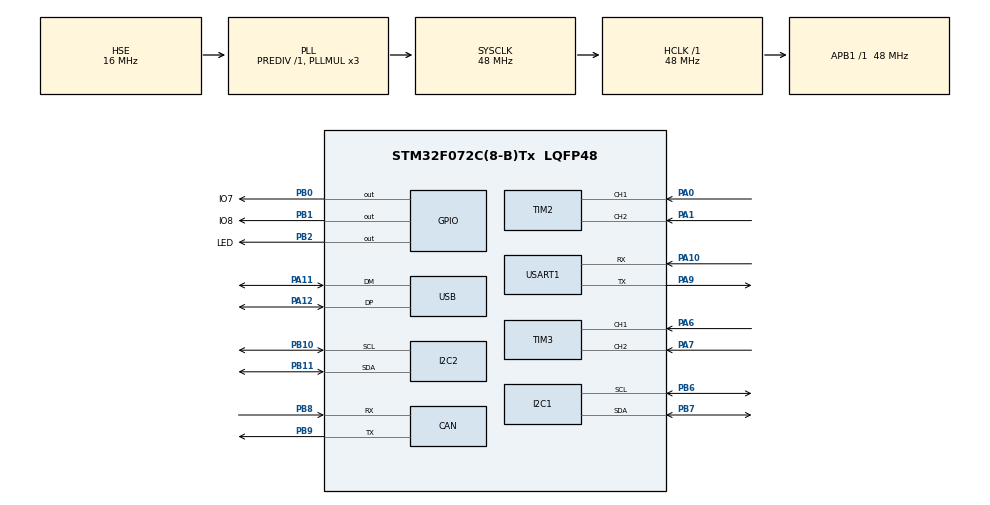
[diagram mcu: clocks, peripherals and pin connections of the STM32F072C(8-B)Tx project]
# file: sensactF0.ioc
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CAN.CalculateTimeQuantum=333.3333333333333
Mcu.Family=STM32F0
Mcu.Name=STM32F072C(8-B)Tx
Mcu.Package=LQFP48
PA0.Signal=S_TIM2_CH1_ETR
PA1.Signal=S_TIM2_CH2
PA10.Mode=Asynchronous
PA10.Signal=USART1_RX
PA11.Mode=Device
PA11.Signal=USB_DM
PA12.Mode=Device
PA12.Signal=USB_DP
PA13.Mode=Serial_Wire
PA13.Signal=SYS_SWDIO
PA14.Mode=Serial_Wire
PA14.Signal=SYS_SWCLK
PA6.Signal=S_TIM3_CH1
PA7.Signal=S_TIM3_CH2
PA9.Mode=Asynchronous
PA9.Signal=USART1_TX
PB0.GPIO_Label=IO7
PB0.Signal=GPIO_Output
PB1.GPIO_Label=IO8
PB1.Signal=GPIO_Output
PB10.Mode=I2C
PB10.Signal=I2C2_SCL
PB11.Mode=I2C
PB11.Signal=I2C2_SDA
PB2.GPIO_Label=LED
PB2.Signal=GPIO_Output
PB6.Mode=I2C
PB6.Signal=I2C1_SCL
PB7.Mode=I2C
PB7.Signal=I2C1_SDA
PB8.Mode=Master
PB8.Signal=CAN_RX
PB9.Mode=Master
PB9.Signal=CAN_TX
PF0-OSC_IN.Mode=HSE-External-Oscillator
PF0-OSC_IN.Signal=RCC_OSC_IN
PF1-OSC_OUT.Mode=HSE-External-Oscillator
PF1-OSC_OUT.Signal=RCC_OSC_OUT
ProjectManager.HeapSize=0x200
ProjectManager.StackSize=0x400
ProjectManager.TargetToolchain=TrueSTUDIO
RCC.AHBFreq_Value=48000000
RCC.APB1Freq_Value=48000000
RCC.APB1TimFreq_Value=48000000
RCC.HCLKFreq_Value=48000000
RCC.HSE_VALUE=16000000
RCC.PLLMUL=RCC_PLL_MUL3
RCC.PLLSourceVirtual=RCC_PLLSOURCE_HSE
RCC.SYSCLKFreq_VALUE=48000000
RCC.SYSCLKSource=RCC_SYSCLKSOURCE_PLLCLK
SH.S_TIM2_CH1_ETR.0=TIM2_CH1,Input_Capture1_from_TI1
SH.S_TIM2_CH2.0=TIM2_CH2,Input_Capture2_from_TI2
SH.S_TIM3_CH1.0=TIM3_CH1,Input_Capture1_from_TI1
SH.S_TIM3_CH2.0=TIM3_CH2,Input_Capture2_from_TI2
TIM2.Channel-Input_Capture1_from_TI1=TIM_CHANNEL_1
TIM2.Channel-Input_Capture2_from_TI2=TIM_CHANNEL_2
TIM3.Channel-Input_Capture1_from_TI1=TIM_CHANNEL_1
TIM3.Channel-Input_Capture2_from_TI2=TIM_CHANNEL_2
USART1.VirtualMode-Asynchronous=VM_ASYNC
VP_TIM2_VS_ClockSourceINT.Mode=Internal
board=sensactF0

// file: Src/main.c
/**
  ******************************************************************************
  * @file           : main.c
  * @brief          : Main program body
  ******************************************************************************
  ** This notice applies to any and all portions of this file
  * that are not between comment pairs USER CODE BEGIN and
  * USER CODE END. Other portions of this file, whether
  * inserted by the user or by software development tools
  * are owned by their respective copyright owners.
  *
  * COPYRIGHT(c) 2018 STMicroelectronics
  *
  * Redistribution and use in source and binary forms, with or without modification,
  * are permitted provided that the following conditions are met:
  *   1. Redistributions of source code must retain the above copyright notice,
  *      this list of conditions and the following disclaimer.
  *   2. Redistributions in binary form must reproduce the above copyright notice,
  *      this list of conditions and the following disclaimer in the documentation
  *      and/or other materials provided with the distribution.
  *   3. Neither the name of STMicroelectronics nor the names of its contributors
  *      may be used to endorse or promote products derived from this software
  *      without specific prior written permission.
  *
  * THIS SOFTWARE IS PROVIDED BY THE COPYRIGHT HOLDERS AND CONTRIBUTORS "AS IS"
  * AND ANY EXPRESS OR IMPLIED WARRANTIES, INCLUDING, BUT NOT LIMITED TO, THE
  * IMPLIED WARRANTIES OF MERCHANTABILITY AND FITNESS FOR A PARTICULAR PURPOSE ARE
  * DISCLAIMED. IN NO EVENT SHALL THE COPYRIGHT HOLDER OR CONTRIBUTORS BE LIABLE
  * FOR ANY DIRECT, INDIRECT, INCIDENTAL, SPECIAL, EXEMPLARY, OR CONSEQUENTIAL
  * DAMAGES (INCLUDING, BUT NOT LIMITED TO, PROCUREMENT OF SUBSTITUTE GOODS OR
  * SERVICES; LOSS OF USE, DATA, OR PROFITS; OR BUSINESS INTERRUPTION) HOWEVER
  * CAUSED AND ON ANY THEORY OF LIABILITY, WHETHER IN CONTRACT, STRICT LIABILITY,
  * OR TORT (INCLUDING NEGLIGENCE OR OTHERWISE) ARISING IN ANY WAY OUT OF THE USE
  * OF THIS SOFTWARE, EVEN IF ADVISED OF THE POSSIBILITY OF SUCH DAMAGE.
  *
  ******************************************************************************
  */
#include "main.h"
#include "stm32f0xx_hal.h"

CAN_HandleTypeDef hcan;

I2C_HandleTypeDef hi2c1;
I2C_HandleTypeDef hi2c2;

TIM_HandleTypeDef htim2;
TIM_HandleTypeDef htim3;

UART_HandleTypeDef huart1;

PCD_HandleTypeDef hpcd_USB_FS;

/* USER CODE BEGIN PV */
/* Private variables ---------------------------------------------------------*/

/* USER CODE END PV */

void SystemClock_Config(void);
static void MX_GPIO_Init(void);
static void MX_USB_PCD_Init(void);
static void MX_USART1_UART_Init(void);
static void MX_I2C1_Init(void);
static void MX_I2C2_Init(void);
static void MX_CAN_Init(void);
static void MX_TIM2_Init(void);
static void MX_TIM3_Init(void);

/* USER CODE BEGIN PFP */
/* Private function prototypes -----------------------------------------------*/

/* USER CODE END PFP */

int main(void)
{

  /* MCU Configuration----------------------------------------------------------*/

  /* Reset of all peripherals, Initializes the Flash interface and the Systick. */
  HAL_Init();

  /* Configure the system clock */
  SystemClock_Config();

  /* Initialize all configured peripherals */
  MX_GPIO_Init();
  MX_USB_PCD_Init();
  MX_USART1_UART_Init();
  MX_I2C1_Init();
  MX_I2C2_Init();
  MX_CAN_Init();
  MX_TIM2_Init();
  MX_TIM3_Init();

  /* Infinite loop */
  /* USER CODE BEGIN WHILE */
  while (1)
  {
	  HAL_Delay(200);
	  HAL_GPIO_TogglePin(GPIOB, GPIO_PIN_1);
  /* USER CODE END WHILE */

  }

}

void SystemClock_Config(void)
{

  RCC_OscInitTypeDef RCC_OscInitStruct;
  RCC_ClkInitTypeDef RCC_ClkInitStruct;
  RCC_PeriphCLKInitTypeDef PeriphClkInit;

    /**Initializes the CPU, AHB and APB busses clocks
    */
  RCC_OscInitStruct.OscillatorType = RCC_OSCILLATORTYPE_HSI|RCC_OSCILLATORTYPE_HSI48
                              |RCC_OSCILLATORTYPE_HSE;
  RCC_OscInitStruct.HSEState = RCC_HSE_ON;
  RCC_OscInitStruct.HSIState = RCC_HSI_ON;
  RCC_OscInitStruct.HSI48State = RCC_HSI48_ON;
  RCC_OscInitStruct.HSICalibrationValue = 16;
  RCC_OscInitStruct.PLL.PLLState = RCC_PLL_ON;
  RCC_OscInitStruct.PLL.PLLSource = RCC_PLLSOURCE_HSE;
  RCC_OscInitStruct.PLL.PLLMUL = RCC_PLL_MUL3;
  RCC_OscInitStruct.PLL.PREDIV = RCC_PREDIV_DIV1;
  if (HAL_RCC_OscConfig(&RCC_OscInitStruct) != HAL_OK)
  {
    _Error_Handler(__FILE__, __LINE__);
  }

    /**Initializes the CPU, AHB and APB busses clocks
    */
  RCC_ClkInitStruct.ClockType = RCC_CLOCKTYPE_HCLK|RCC_CLOCKTYPE_SYSCLK
                              |RCC_CLOCKTYPE_PCLK1;
  RCC_ClkInitStruct.SYSCLKSource = RCC_SYSCLKSOURCE_PLLCLK;
  RCC_ClkInitStruct.AHBCLKDivider = RCC_SYSCLK_DIV1;
  RCC_ClkInitStruct.APB1CLKDivider = RCC_HCLK_DIV1;

  if (HAL_RCC_ClockConfig(&RCC_ClkInitStruct, FLASH_LATENCY_1) != HAL_OK)
  {
    _Error_Handler(__FILE__, __LINE__);
  }

  PeriphClkInit.PeriphClockSelection = RCC_PERIPHCLK_USB|RCC_PERIPHCLK_USART1
                              |RCC_PERIPHCLK_I2C1;
  PeriphClkInit.Usart1ClockSelection = RCC_USART1CLKSOURCE_PCLK1;
  PeriphClkInit.I2c1ClockSelection = RCC_I2C1CLKSOURCE_HSI;
  PeriphClkInit.UsbClockSelection = RCC_USBCLKSOURCE_HSI48;

  if (HAL_RCCEx_PeriphCLKConfig(&PeriphClkInit) != HAL_OK)
  {
    _Error_Handler(__FILE__, __LINE__);
  }

    /**Configure the Systick interrupt time
    */
  HAL_SYSTICK_Config(HAL_RCC_GetHCLKFreq()/1000);

    /**Configure the Systick
    */
  HAL_SYSTICK_CLKSourceConfig(SYSTICK_CLKSOURCE_HCLK);

  /* SysTick_IRQn interrupt configuration */
  HAL_NVIC_SetPriority(SysTick_IRQn, 0, 0);
}

/* CAN init function */
static void MX_CAN_Init(void)
{

  hcan.Instance = CAN;
  hcan.Init.Prescaler = 16;
  hcan.Init.Mode = CAN_MODE_NORMAL;
  hcan.Init.SJW = CAN_SJW_1TQ;
  hcan.Init.BS1 = CAN_BS1_1TQ;
  hcan.Init.BS2 = CAN_BS2_1TQ;
  hcan.Init.TTCM = DISABLE;
  hcan.Init.ABOM = DISABLE;
  hcan.Init.AWUM = DISABLE;
  hcan.Init.NART = DISABLE;
  hcan.Init.RFLM = DISABLE;
  hcan.Init.TXFP = DISABLE;
  if (HAL_CAN_Init(&hcan) != HAL_OK)
  {
    _Error_Handler(__FILE__, __LINE__);
  }

}

/* I2C1 init function */
static void MX_I2C1_Init(void)
{

  hi2c1.Instance = I2C1;
  hi2c1.Init.Timing = 0x2000090E;
  hi2c1.Init.OwnAddress1 = 0;
  hi2c1.Init.AddressingMode = I2C_ADDRESSINGMODE_7BIT;
  hi2c1.Init.DualAddressMode = I2C_DUALADDRESS_DISABLE;
  hi2c1.Init.OwnAddress2 = 0;
  hi2c1.Init.OwnAddress2Masks = I2C_OA2_NOMASK;
  hi2c1.Init.GeneralCallMode = I2C_GENERALCALL_DISABLE;
  hi2c1.Init.NoStretchMode = I2C_NOSTRETCH_DISABLE;
  if (HAL_I2C_Init(&hi2c1) != HAL_OK)
  {
    _Error_Handler(__FILE__, __LINE__);
  }

    /**Configure Analogue filter
    */
  if (HAL_I2CEx_ConfigAnalogFilter(&hi2c1, I2C_ANALOGFILTER_ENABLE) != HAL_OK)
  {
    _Error_Handler(__FILE__, __LINE__);
  }

    /**Configure Digital filter
    */
  if (HAL_I2CEx_ConfigDigitalFilter(&hi2c1, 0) != HAL_OK)
  {
    _Error_Handler(__FILE__, __LINE__);
  }

}

/* I2C2 init function */
static void MX_I2C2_Init(void)
{

  hi2c2.Instance = I2C2;
  hi2c2.Init.Timing = 0x2000090E;
  hi2c2.Init.OwnAddress1 = 0;
  hi2c2.Init.AddressingMode = I2C_ADDRESSINGMODE_7BIT;
  hi2c2.Init.DualAddressMode = I2C_DUALADDRESS_DISABLE;
  hi2c2.Init.OwnAddress2 = 0;
  hi2c2.Init.OwnAddress2Masks = I2C_OA2_NOMASK;
  hi2c2.Init.GeneralCallMode = I2C_GENERALCALL_DISABLE;
  hi2c2.Init.NoStretchMode = I2C_NOSTRETCH_DISABLE;
  if (HAL_I2C_Init(&hi2c2) != HAL_OK)
  {
    _Error_Handler(__FILE__, __LINE__);
  }

    /**Configure Analogue filter
    */
  if (HAL_I2CEx_ConfigAnalogFilter(&hi2c2, I2C_ANALOGFILTER_ENABLE) != HAL_OK)
  {
    _Error_Handler(__FILE__, __LINE__);
  }

    /**Configure Digital filter
    */
  if (HAL_I2CEx_ConfigDigitalFilter(&hi2c2, 0) != HAL_OK)
  {
    _Error_Handler(__FILE__, __LINE__);
  }

}

/* TIM2 init function */
static void MX_TIM2_Init(void)
{

  TIM_ClockConfigTypeDef sClockSourceConfig;
  TIM_MasterConfigTypeDef sMasterConfig;
  TIM_IC_InitTypeDef sConfigIC;

  htim2.Instance = TIM2;
  htim2.Init.Prescaler = 0;
  htim2.Init.CounterMode = TIM_COUNTERMODE_UP;
  htim2.Init.Period = 0;
  htim2.Init.ClockDivision = TIM_CLOCKDIVISION_DIV1;
  htim2.Init.AutoReloadPreload = TIM_AUTORELOAD_PRELOAD_DISABLE;
  if (HAL_TIM_Base_Init(&htim2) != HAL_OK)
  {
    _Error_Handler(__FILE__, __LINE__);
  }

  sClockSourceConfig.ClockSource = TIM_CLOCKSOURCE_INTERNAL;
  if (HAL_TIM_ConfigClockSource(&htim2, &sClockSourceConfig) != HAL_OK)
  {
    _Error_Handler(__FILE__, __LINE__);
  }

  if (HAL_TIM_IC_Init(&htim2) != HAL_OK)
  {
    _Error_Handler(__FILE__, __LINE__);
  }

  sMasterConfig.MasterOutputTrigger = TIM_TRGO_RESET;
  sMasterConfig.MasterSlaveMode = TIM_MASTERSLAVEMODE_DISABLE;
  if (HAL_TIMEx_MasterConfigSynchronization(&htim2, &sMasterConfig) != HAL_OK)
  {
    _Error_Handler(__FILE__, __LINE__);
  }

  sConfigIC.ICPolarity = TIM_INPUTCHANNELPOLARITY_RISING;
  sConfigIC.ICSelection = TIM_ICSELECTION_DIRECTTI;
  sConfigIC.ICPrescaler = TIM_ICPSC_DIV1;
  sConfigIC.ICFilter = 0;
  if (HAL_TIM_IC_ConfigChannel(&htim2, &sConfigIC, TIM_CHANNEL_1) != HAL_OK)
  {
    _Error_Handler(__FILE__, __LINE__);
  }

  if (HAL_TIM_IC_ConfigChannel(&htim2, &sConfigIC, TIM_CHANNEL_2) != HAL_OK)
  {
    _Error_Handler(__FILE__, __LINE__);
  }

}

/* TIM3 init function */
static void MX_TIM3_Init(void)
{

  TIM_MasterConfigTypeDef sMasterConfig;
  TIM_IC_InitTypeDef sConfigIC;

  htim3.Instance = TIM3;
  htim3.Init.Prescaler = 0;
  htim3.Init.CounterMode = TIM_COUNTERMODE_UP;
  htim3.Init.Period = 0;
  htim3.Init.ClockDivision = TIM_CLOCKDIVISION_DIV1;
  htim3.Init.AutoReloadPreload = TIM_AUTORELOAD_PRELOAD_DISABLE;
  if (HAL_TIM_IC_Init(&htim3) != HAL_OK)
  {
    _Error_Handler(__FILE__, __LINE__);
  }

  sMasterConfig.MasterOutputTrigger = TIM_TRGO_RESET;
  sMasterConfig.MasterSlaveMode = TIM_MASTERSLAVEMODE_DISABLE;
  if (HAL_TIMEx_MasterConfigSynchronization(&htim3, &sMasterConfig) != HAL_OK)
  {
    _Error_Handler(__FILE__, __LINE__);
  }

  sConfigIC.ICPolarity = TIM_INPUTCHANNELPOLARITY_RISING;
  sConfigIC.ICSelection = TIM_ICSELECTION_DIRECTTI;
  sConfigIC.ICPrescaler = TIM_ICPSC_DIV1;
  sConfigIC.ICFilter = 0;
  if (HAL_TIM_IC_ConfigChannel(&htim3, &sConfigIC, TIM_CHANNEL_1) != HAL_OK)
  {
    _Error_Handler(__FILE__, __LINE__);
  }

  if (HAL_TIM_IC_ConfigChannel(&htim3, &sConfigIC, TIM_CHANNEL_2) != HAL_OK)
  {
    _Error_Handler(__FILE__, __LINE__);
  }

}

/* USART1 init function */
static void MX_USART1_UART_Init(void)
{

  huart1.Instance = USART1;
  huart1.Init.BaudRate = 38400;
  huart1.Init.WordLength = UART_WORDLENGTH_7B;
  huart1.Init.StopBits = UART_STOPBITS_1;
  huart1.Init.Parity = UART_PARITY_NONE;
  huart1.Init.Mode = UART_MODE_TX_RX;
  huart1.Init.HwFlowCtl = UART_HWCONTROL_NONE;
  huart1.Init.OverSampling = UART_OVERSAMPLING_16;
  huart1.Init.OneBitSampling = UART_ONE_BIT_SAMPLE_DISABLE;
  huart1.AdvancedInit.AdvFeatureInit = UART_ADVFEATURE_NO_INIT;
  if (HAL_UART_Init(&huart1) != HAL_OK)
  {
    _Error_Handler(__FILE__, __LINE__);
  }

}

/* USB init function */
static void MX_USB_PCD_Init(void)
{

  hpcd_USB_FS.Instance = USB;
  hpcd_USB_FS.Init.dev_endpoints = 8;
  hpcd_USB_FS.Init.speed = PCD_SPEED_FULL;
  hpcd_USB_FS.Init.ep0_mps = DEP0CTL_MPS_64;
  hpcd_USB_FS.Init.phy_itface = PCD_PHY_EMBEDDED;
  hpcd_USB_FS.Init.low_power_enable = DISABLE;
  hpcd_USB_FS.Init.lpm_enable = DISABLE;
  hpcd_USB_FS.Init.battery_charging_enable = DISABLE;
  if (HAL_PCD_Init(&hpcd_USB_FS) != HAL_OK)
  {
    _Error_Handler(__FILE__, __LINE__);
  }

}

/** Configure pins as
        * Analog
        * Input
        * Output
        * EVENT_OUT
        * EXTI
*/
static void MX_GPIO_Init(void)
{

  GPIO_InitTypeDef GPIO_InitStruct;

  /* GPIO Ports Clock Enable */
  __HAL_RCC_GPIOF_CLK_ENABLE();
  __HAL_RCC_GPIOA_CLK_ENABLE();
  __HAL_RCC_GPIOB_CLK_ENABLE();

  /*Configure GPIO pin Output Level */
  HAL_GPIO_WritePin(GPIOB, IO7_Pin|IO8_Pin|LED_Pin, GPIO_PIN_RESET);

  /*Configure GPIO pins : IO7_Pin IO8_Pin LED_Pin */
  GPIO_InitStruct.Pin = IO7_Pin|IO8_Pin|LED_Pin;
  GPIO_InitStruct.Mode = GPIO_MODE_OUTPUT_PP;
  GPIO_InitStruct.Pull = GPIO_NOPULL;
  GPIO_InitStruct.Speed = GPIO_SPEED_FREQ_LOW;
  HAL_GPIO_Init(GPIOB, &GPIO_InitStruct);

}

void _Error_Handler(char *file, int line)
{
  while(1)
  {
  }
}

/************************ (C) COPYRIGHT STMicroelectronics *****END OF FILE****/
